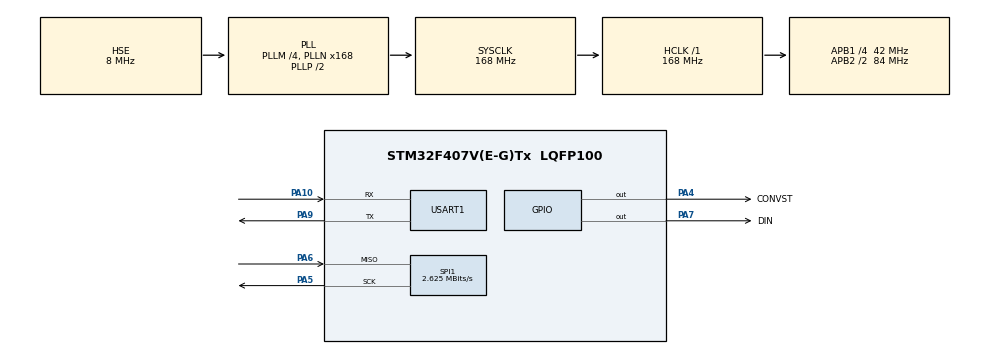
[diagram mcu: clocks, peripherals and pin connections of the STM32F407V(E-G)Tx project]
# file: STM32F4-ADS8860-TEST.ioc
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Mcu.Family=STM32F4
Mcu.Name=STM32F407V(E-G)Tx
Mcu.Package=LQFP100
NVIC.PriorityGroup=NVIC_PRIORITYGROUP_4
PA10.Mode=Asynchronous
PA10.Signal=USART1_RX
PA13.Mode=Serial_Wire
PA13.Signal=SYS_JTMS-SWDIO
PA14.Mode=Serial_Wire
PA14.Signal=SYS_JTCK-SWCLK
PA4.GPIO_Label=CONVST
PA4.GPIO_PuPd=GPIO_PULLUP
PA4.GPIO_Speed=GPIO_SPEED_FREQ_HIGH
PA4.Signal=GPIO_Output
PA5.GPIO_PuPd=GPIO_PULLUP
PA5.Mode=RX_Only_Simplex_Unidirect_Master
PA5.Signal=SPI1_SCK
PA6.GPIO_PuPd=GPIO_PULLUP
PA6.Mode=RX_Only_Simplex_Unidirect_Master
PA6.Signal=SPI1_MISO
PA7.GPIO_Label=DIN
PA7.GPIO_PuPd=GPIO_PULLUP
PA7.GPIO_Speed=GPIO_SPEED_FREQ_HIGH
PA7.Signal=GPIO_Output
PA9.Mode=Asynchronous
PA9.Signal=USART1_TX
PH0-OSC_IN.Mode=HSE-External-Oscillator
PH0-OSC_IN.Signal=RCC_OSC_IN
PH1-OSC_OUT.Mode=HSE-External-Oscillator
PH1-OSC_OUT.Signal=RCC_OSC_OUT
ProjectManager.HeapSize=0x200
ProjectManager.StackSize=0x400
ProjectManager.TargetToolchain=MDK-ARM V5
RCC.48MHZClocksFreq_Value=84000000
RCC.AHBFreq_Value=168000000
RCC.APB1CLKDivider=RCC_HCLK_DIV4
RCC.APB1Freq_Value=42000000
RCC.APB1TimFreq_Value=84000000
RCC.APB2CLKDivider=RCC_HCLK_DIV2
RCC.APB2Freq_Value=84000000
RCC.APB2TimFreq_Value=168000000
RCC.CortexFreq_Value=168000000
RCC.HCLKFreq_Value=168000000
RCC.HSE_VALUE=8000000
RCC.HSI_VALUE=16000000
RCC.LSE_VALUE=32768
RCC.PLLM=4
RCC.PLLN=168
RCC.PLLSourceVirtual=RCC_PLLSOURCE_HSE
RCC.SYSCLKFreq_VALUE=168000000
RCC.SYSCLKSource=RCC_SYSCLKSOURCE_PLLCLK
RCC.VCOOutputFreq_Value=336000000
SPI1.BaudRatePrescaler=SPI_BAUDRATEPRESCALER_32
SPI1.CLKPhase=SPI_PHASE_1EDGE
SPI1.CLKPolarity=SPI_POLARITY_LOW
SPI1.CalculateBaudRate=2.625 MBits/s
SPI1.DataSize=SPI_DATASIZE_8BIT
SPI1.Direction=SPI_DIRECTION_2LINES_RXONLY
SPI1.Mode=SPI_MODE_MASTER
SPI1.VirtualType=VM_MASTER
USART1.VirtualMode=VM_ASYNC
board=custom

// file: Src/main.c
/* USER CODE BEGIN Header */

/* USER CODE END Header */

#include "main.h"
#include "spi.h"
#include "usart.h"
#include "gpio.h"

/* USER CODE BEGIN Includes */
#include "ads8860.h"

/* USER CODE END Includes */

/* USER CODE BEGIN PV */
double waveform[2000];
/* USER CODE END PV */

void SystemClock_Config(void);

int main(void)
{
  /* USER CODE BEGIN 1 */
	uint16_t adc = 0;
	double volt = 0;
  /* USER CODE END 1 */

  /* MCU Configuration--------------------------------------------------------*/

  /* Reset of all peripherals, Initializes the Flash interface and the Systick. */
  HAL_Init();

  /* Configure the system clock */
  SystemClock_Config();

  /* Initialize all configured peripherals */
  MX_GPIO_Init();
  MX_SPI1_Init();
  MX_USART1_UART_Init();
  /* USER CODE BEGIN 2 */
	printf("\n\r UART Test Passed~ \n\r");
	ads8860_Init();
  /* USER CODE END 2 */

  /* Infinite loop */
  /* USER CODE BEGIN WHILE */
  while (1)
  {
		//printf("\n\r UART Working... \n\r");
		adc = ADS8860_ReadValue();
		volt = (double)adc*5.058/65535;
		//printf("\r\nraw = %d\r\n", adc);
		printf("volt = %.3f\r\n", volt);
		HAL_Delay(1);

//		HAL_Delay(1);
//

		//HAL_Delay(5000);
    /* USER CODE END WHILE */

  }
}

void SystemClock_Config(void)
{
  RCC_OscInitTypeDef RCC_OscInitStruct = {0};
  RCC_ClkInitTypeDef RCC_ClkInitStruct = {0};

  /**Configure the main internal regulator output voltage
  */
  __HAL_RCC_PWR_CLK_ENABLE();
  __HAL_PWR_VOLTAGESCALING_CONFIG(PWR_REGULATOR_VOLTAGE_SCALE1);
  /**Initializes the CPU, AHB and APB busses clocks
  */
  RCC_OscInitStruct.OscillatorType = RCC_OSCILLATORTYPE_HSE;
  RCC_OscInitStruct.HSEState = RCC_HSE_ON;
  RCC_OscInitStruct.PLL.PLLState = RCC_PLL_ON;
  RCC_OscInitStruct.PLL.PLLSource = RCC_PLLSOURCE_HSE;
  RCC_OscInitStruct.PLL.PLLM = 4;
  RCC_OscInitStruct.PLL.PLLN = 168;
  RCC_OscInitStruct.PLL.PLLP = RCC_PLLP_DIV2;
  RCC_OscInitStruct.PLL.PLLQ = 4;
  if (HAL_RCC_OscConfig(&RCC_OscInitStruct) != HAL_OK)
  {
    Error_Handler();
  }
  /**Initializes the CPU, AHB and APB busses clocks
  */
  RCC_ClkInitStruct.ClockType = RCC_CLOCKTYPE_HCLK|RCC_CLOCKTYPE_SYSCLK
                              |RCC_CLOCKTYPE_PCLK1|RCC_CLOCKTYPE_PCLK2;
  RCC_ClkInitStruct.SYSCLKSource = RCC_SYSCLKSOURCE_PLLCLK;
  RCC_ClkInitStruct.AHBCLKDivider = RCC_SYSCLK_DIV1;
  RCC_ClkInitStruct.APB1CLKDivider = RCC_HCLK_DIV4;
  RCC_ClkInitStruct.APB2CLKDivider = RCC_HCLK_DIV2;

  if (HAL_RCC_ClockConfig(&RCC_ClkInitStruct, FLASH_LATENCY_5) != HAL_OK)
  {
    Error_Handler();
  }
}

void Error_Handler(void)
{
}

/************************ (C) COPYRIGHT STMicroelectronics *****END OF FILE****/
